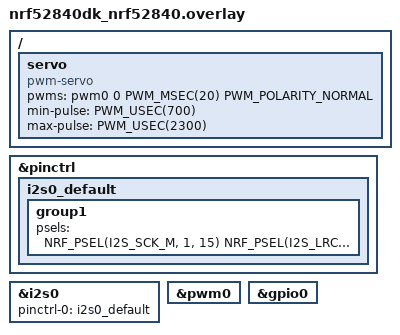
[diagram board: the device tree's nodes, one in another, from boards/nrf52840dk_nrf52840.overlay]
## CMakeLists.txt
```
# SPDX-License-Identifier: Apache-2.0

cmake_minimum_required(VERSION 3.20.0)
find_package(Zephyr REQUIRED HINTS $ENV{ZEPHYR_BASE})
project(base)

target_sources(app PRIVATE src/main.c)

target_include_directories(app PRIVATE ${CMAKE_CURRENT_SOURCE_DIR}/include)
```

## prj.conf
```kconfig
CONFIG_STDOUT_CONSOLE=y
CONFIG_PRINTK=y
CONFIG_PWM=y

CONFIG_I2S=y
CONFIG_LOG=y
```

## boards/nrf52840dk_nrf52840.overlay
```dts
&pinctrl {
    i2s0_default: i2s0_default {
        group1 {
            psels = <
                NRF_PSEL(I2S_SCK_M, 1, 15)     // BCLK
                NRF_PSEL(I2S_LRCK_M, 1, 12)    // LRCK
                NRF_PSEL(I2S_SDOUT, 1, 13)     // SDOUT
            >;
        };
    };
};

&i2s0 {
    status = "okay";
    pinctrl-0 = <&i2s0_default>;
    pinctrl-names = "default";
};

&pwm0 {
    status = "okay";
};

&gpio0 {
    status = "okay";
};

 / {
    servo: servo {
        compatible = "pwm-servo";
        pwms = <&pwm0 0 PWM_MSEC(20) PWM_POLARITY_NORMAL>; // channel 0 (P0.13)
        min-pulse = <PWM_USEC(700)>;
        max-pulse = <PWM_USEC(2300)>;
    };
};
```

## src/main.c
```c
#include <zephyr/kernel.h>
#include <zephyr/sys/printk.h>
#include <zephyr/device.h>
#include <zephyr/drivers/pwm.h>

// Servo device and pulse width limits from Devicetree
static const struct pwm_dt_spec servo = PWM_DT_SPEC_GET(DT_NODELABEL(servo));
static const uint32_t min_pulse = DT_PROP(DT_NODELABEL(servo), min_pulse);
static const uint32_t max_pulse = DT_PROP(DT_NODELABEL(servo), max_pulse);

// Direction enum
enum direction {
	DOWN,
	UP,
};

// Global direction state
static enum direction dir = UP;

// Toggle servo between min and max pulse widths
void unlock_or_lock(void) {
    uint32_t pulse_width = (dir == UP) ? max_pulse : min_pulse;

    int ret = pwm_set_pulse_dt(&servo, pulse_width);
    if (ret < 0) {
        printk("Error %d: failed to set pulse width\n", ret);
        return;
    }

    printk("Moved to %s (pulse: %d us)\n", dir == UP ? "180°" : "0°", pulse_width);

    // Flip direction
    dir = (dir == UP) ? DOWN : UP;
}

int main(void) {
	printk("Servomotor control\n");

	if (!pwm_is_ready_dt(&servo)) {
		printk("Error: PWM device %s is not ready\n", servo.dev->name);
		return 0;
	}

	// Initialize to 0°
    pwm_set_pulse_dt(&servo, min_pulse);
    dir = UP;

    while (1) {
        k_sleep(K_SECONDS(5));
        unlock_or_lock();
        printk("Servo toggled\n");
    }

	return 0;
}


// #include <stdio.h>
// #include <zephyr/kernel.h>
// #include <zephyr/drivers/i2s.h>
// #include <zephyr/sys/iterable_sections.h>

// #define SAMPLE_NO 64

// /* The data represent a sine wave */
// static int16_t data[SAMPLE_NO] = {
// 	  3211,   6392,   9511,  12539,  15446,  18204,  20787,  23169,
// 	 25329,  27244,  28897,  30272,  31356,  32137,  32609,  32767,
// 	 32609,  32137,  31356,  30272,  28897,  27244,  25329,  23169,
// 	 20787,  18204,  15446,  12539,   9511,   6392,   3211,      0,
// 	 -3212,  -6393,  -9512, -12540, -15447, -18205, -20788, -23170,
// 	-25330, -27245, -28898, -30273, -31357, -32138, -32610, -32767,
// 	-32610, -32138, -31357, -30273, -28898, -27245, -25330, -23170,
// 	-20788, -18205, -15447, -12540,  -9512,  -6393,  -3212,     -1,
// };

// /* Fill buffer with sine wave on left channel, and sine wave shifted by
//  * 90 degrees on right channel. "att" represents a power of two to attenuate
//  * the samples by
//  */
// static void fill_buf(int16_t *tx_block, int att)
// {
// 	int r_idx;

// 	for (int i = 0; i < SAMPLE_NO; i++) {
// 		/* Left channel is sine wave */
// 		tx_block[2 * i] = data[i] / (1 << att);
// 		/* Right channel is same sine wave, shifted by 90 degrees */
// 		r_idx = (i + (ARRAY_SIZE(data) / 4)) % ARRAY_SIZE(data);
// 		tx_block[2 * i + 1] = data[r_idx] / (1 << att);
// 	}
// }

// #define NUM_BLOCKS 20
// #define BLOCK_SIZE (2 * sizeof(data))

// #ifdef CONFIG_NOCACHE_MEMORY
// 	#define MEM_SLAB_CACHE_ATTR __nocache
// #else
// 	#define MEM_SLAB_CACHE_ATTR
// #endif /* CONFIG_NOCACHE_MEMORY */

// static char MEM_SLAB_CACHE_ATTR __aligned(WB_UP(32))
// 	_k_mem_slab_buf_tx_0_mem_slab[(NUM_BLOCKS) * WB_UP(BLOCK_SIZE)];

// static STRUCT_SECTION_ITERABLE(k_mem_slab, tx_0_mem_slab) =
// 	Z_MEM_SLAB_INITIALIZER(tx_0_mem_slab, _k_mem_slab_buf_tx_0_mem_slab,
// 				WB_UP(BLOCK_SIZE), NUM_BLOCKS);

// void play_tone_for_seconds(const struct device *dev_i2s, int seconds)
// {
// 	int ret;
// 	void *tx_buf;

// 	// Calculate total samples to send: rate * seconds
// 	uint32_t total_samples = 96000 * seconds;
// 	uint32_t samples_per_block = BLOCK_SIZE / (sizeof(int16_t) * 2);  // Stereo: 2 channels
// 	uint32_t total_blocks = (total_samples + samples_per_block - 1) / samples_per_block;

// 	// Start the stream
// 	ret = i2s_trigger(dev_i2s, I2S_DIR_TX, I2S_TRIGGER_START);
// 	if (ret < 0) {
// 		printf("I2S trigger start failed\n");
// 		return;
// 	}

// 	for (uint32_t i = 0; i < total_blocks; i++) {
// 		ret = k_mem_slab_alloc(&tx_0_mem_slab, &tx_buf, K_FOREVER);
// 		if (ret < 0) {
// 			printf("TX slab alloc failed\n");
// 			break;
// 		}

// 		fill_buf((int16_t *)tx_buf, i % 3);  // Optional modulation
// 		ret = i2s_write(dev_i2s, tx_buf, BLOCK_SIZE);
// 		if (ret < 0) {
// 			printf("TX write failed\n");
// 			k_mem_slab_free(&tx_0_mem_slab, &tx_buf);
// 			break;
// 		}
// 	}

// 	// Drain and stop
// 	i2s_trigger(dev_i2s, I2S_DIR_TX, I2S_TRIGGER_DRAIN);
// }


// int main(void)
// {
// 	void *tx_block[NUM_BLOCKS];
// 	struct i2s_config i2s_cfg;
// 	int ret;
// 	uint32_t tx_idx;
// 	const struct device *dev_i2s =  DEVICE_DT_GET(DT_NODELABEL(i2s0));

// 	if (!device_is_ready(dev_i2s)) {
// 		printf("I2S device not ready\n");
// 		return -ENODEV;
// 	}
// 	/* Configure I2S stream */
// 	i2s_cfg.word_size = 16U;
// 	i2s_cfg.channels = 2U;
// 	i2s_cfg.format = I2S_FMT_DATA_FORMAT_I2S;
// 	i2s_cfg.frame_clk_freq = 96000;
// 	i2s_cfg.block_size = BLOCK_SIZE;
// 	i2s_cfg.timeout = 2000;
// 	/* Configure the Transmit port as Master */
// 	i2s_cfg.options = I2S_OPT_FRAME_CLK_MASTER
// 			| I2S_OPT_BIT_CLK_MASTER;
// 	i2s_cfg.mem_slab = &tx_0_mem_slab;
// 	ret = i2s_configure(dev_i2s, I2S_DIR_TX, &i2s_cfg);
// 	if (ret < 0) {
// 		printf("Failed to configure I2S stream\n");
// 		return ret;
// 	}

//     printf("Playing tone for 3 seconds...\n");
// 	play_tone_for_seconds(dev_i2s, 10);
// 	printf("Done.\n");

// 	// /* Prepare all TX blocks */
// 	// for (tx_idx = 0; tx_idx < NUM_BLOCKS; tx_idx++) {
// 	// 	ret = k_mem_slab_alloc(&tx_0_mem_slab, &tx_block[tx_idx],
// 	// 			       K_FOREVER);
// 	// 	if (ret < 0) {
// 	// 		printf("Failed to allocate TX block\n");
// 	// 		return ret;
// 	// 	}
// 	// 	fill_buf((uint16_t *)tx_block[tx_idx], tx_idx % 3);
// 	// }

// 	// tx_idx = 0;
// 	// /* Send first block */
// 	// ret = i2s_write(dev_i2s, tx_block[tx_idx++], BLOCK_SIZE);
// 	// if (ret < 0) {
// 	// 	printf("Could not write TX buffer %d\n", tx_idx);
// 	// 	return ret;
// 	// }
// 	// /* Trigger the I2S transmission */
// 	// ret = i2s_trigger(dev_i2s, I2S_DIR_TX, I2S_TRIGGER_START);
// 	// if (ret < 0) {
// 	// 	printf("Could not trigger I2S tx\n");
// 	// 	return ret;
// 	// }

// 	// for (; tx_idx < NUM_BLOCKS; ) {
// 	// 	ret = i2s_write(dev_i2s, tx_block[tx_idx++], BLOCK_SIZE);
// 	// 	if (ret < 0) {
// 	// 		printf("Could not write TX buffer %d\n", tx_idx);
// 	// 		return ret;
// 	// 	}
// 	// }
// 	// /* Drain TX queue */
// 	// ret = i2s_trigger(dev_i2s, I2S_DIR_TX, I2S_TRIGGER_DRAIN);
// 	// if (ret < 0) {
// 	// 	printf("Could not trigger I2S tx\n");
// 	// 	return ret;
// 	// }
// 	// printf("All I2S blocks written\n");
// 	// return 0;
// }
```
